VERSION ""

NS_ :

BS_:

BU_: MC_BRUSHED LISTENER COMMANDER REQUESTER

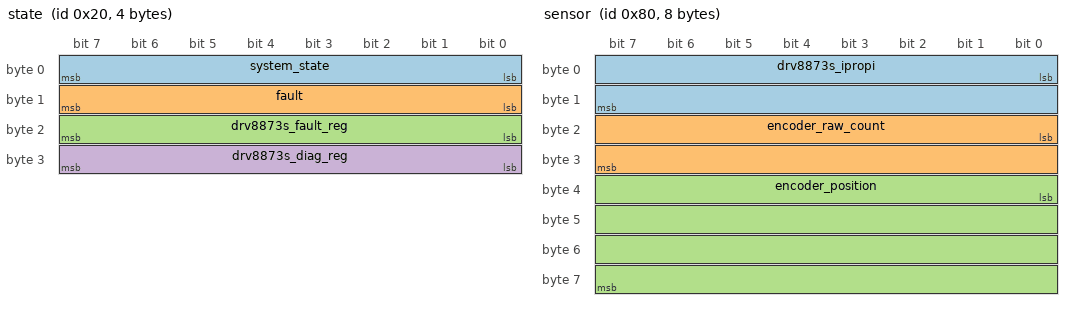
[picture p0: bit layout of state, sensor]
BO_ 32 state: 4 MC_BRUSHED
 SG_ system_state : 0|8@1+ (1,0) [0|255] ""  LISTENER
 SG_ fault : 8|8@1+ (1,0) [0|255] ""  LISTENER
 SG_ drv8873s_fault_reg : 16|8@1+ (1,0) [0|255] ""  LISTENER
 SG_ drv8873s_diag_reg : 24|8@1+ (1,0) [0|255] ""  LISTENER

BO_ 64 command_brushed: 6 COMMANDER
 SG_ node_id : 0|8@1+ (1,0) [0|255] ""  MC_BRUSHED
 SG_ control_mode M : 8|3@1+ (1,0) [0|7] ""  MC_BRUSHED
 SG_ enable : 11|1@1+ (1,0) [0|1] ""  MC_BRUSHED
 SG_ clear_faults : 12|1@1+ (1,0) [0|1] ""  MC_BRUSHED
 SG_ reserved0 : 13|3@1+ (1,0) [0|7] ""  MC_BRUSHED
 SG_ target_torque m1 : 16|32@1- (0.0001,0) [-214748.3648|214748.3647] "Nm"  MC_BRUSHED
 SG_ target_velocity m2 : 16|32@1- (0.001,0) [-2147483.648|2147483.647] "rad/s"  MC_BRUSHED
 SG_ target_position_rel m3 : 16|32@1- (0.001,0) [-2147483.648|2147483.647] "rad"  MC_BRUSHED
 SG_ target_hbridge_ol m4 : 16|32@1- (0.0001,0) [-1|1] ""  MC_BRUSHED

BO_ 96 command_brushed_zero: 1 COMMANDER
 SG_ node_id : 0|8@1+ (1,0) [0|255] ""  MC_BRUSHED

BO_ 128 sensor: 8 MC_BRUSHED
 SG_ drv8873s_ipropi : 0|16@1+ (1,0) [0|4095] "count"  LISTENER
 SG_ encoder_raw_count : 16|16@1- (1,0) [-32768|32767] "count"  LISTENER
 SG_ encoder_position : 32|32@1- (0.001,0) [-2147483.648|2147483.647] "rad"  LISTENER

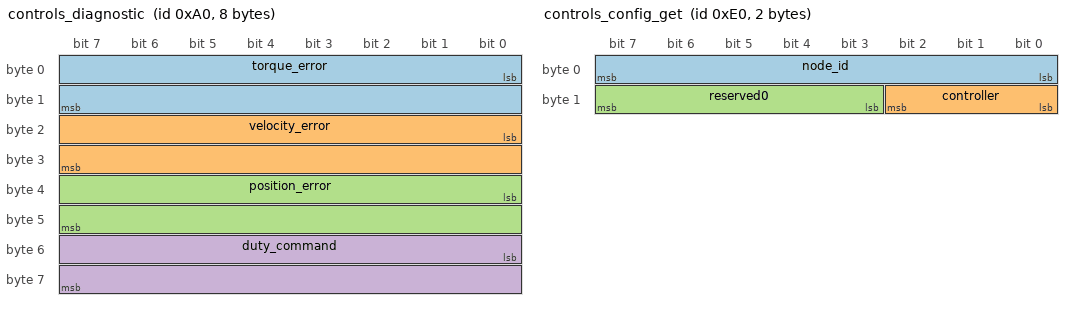
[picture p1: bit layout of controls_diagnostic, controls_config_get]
BO_ 160 controls_diagnostic: 8 MC_BRUSHED
 SG_ torque_error : 0|16@1- (0.001,0) [-32.768|32.767] "Nm"  LISTENER
 SG_ velocity_error : 16|16@1- (0.001,0) [-32.768|32.767] "rad/s"  LISTENER
 SG_ position_error : 32|16@1- (0.0001,0) [-3.2768|3.2767] "rad"  LISTENER
 SG_ duty_command : 48|16@1- (0.0001,0) [-1|1] ""  LISTENER

BO_ 192 controls_config_set: 8 COMMANDER
 SG_ node_id : 0|8@1+ (1,0) [0|255] ""  MC_BRUSHED
 SG_ controller M : 8|3@1+ (1,0) [0|7] ""  MC_BRUSHED
 SG_ reserved0 : 11|5@1+ (1,0) [0|31] ""  MC_BRUSHED
 SG_ torque_k_p m0 : 16|16@1+ (0.001,0) [0|65.535] ""  MC_BRUSHED
 SG_ velocity_k_p m1 : 16|16@1+ (0.001,0) [0|65.535] ""  MC_BRUSHED
 SG_ position_k_p m2 : 16|16@1+ (0.001,0) [0|65.535] ""  MC_BRUSHED
 SG_ torque_k_i m0 : 32|16@1+ (0.001,0) [0|65.535] ""  MC_BRUSHED
 SG_ velocity_k_i m1 : 32|16@1+ (0.001,0) [0|65.535] ""  MC_BRUSHED
 SG_ position_k_i m2 : 32|16@1+ (0.001,0) [0|65.535] ""  MC_BRUSHED
 SG_ torque_k_d m0 : 48|16@1+ (0.001,0) [0|65.535] ""  MC_BRUSHED
 SG_ velocity_k_d m1 : 48|16@1+ (0.001,0) [0|65.535] ""  MC_BRUSHED
 SG_ position_k_d m2 : 48|16@1+ (0.001,0) [0|65.535] ""  MC_BRUSHED

BO_ 224 controls_config_get: 2 REQUESTER
 SG_ node_id : 0|8@1+ (1,0) [0|255] ""  MC_BRUSHED
 SG_ controller M : 8|3@1+ (1,0) [0|7] ""  MC_BRUSHED
 SG_ reserved0 : 11|5@1+ (1,0) [0|31] ""  MC_BRUSHED

BO_ 256 controls_config_response: 8 MC_BRUSHED
 SG_ reserved0 : 0|8@1+ (1,0) [0|255] ""  REQUESTER
 SG_ controller M : 8|3@1+ (1,0) [0|7] ""  REQUESTER
 SG_ reserved1 : 11|5@1+ (1,0) [0|31] ""  REQUESTER
 SG_ torque_k_p m0 : 16|16@1+ (0.001,0) [0|65.535] ""  REQUESTER
 SG_ velocity_k_p m1 : 16|16@1+ (0.001,0) [0|65.535] ""  REQUESTER
 SG_ position_k_p m2 : 16|16@1+ (0.001,0) [0|65.535] ""  REQUESTER
 SG_ torque_k_i m0 : 32|16@1+ (0.001,0) [0|65.535] ""  REQUESTER
 SG_ velocity_k_i m1 : 32|16@1+ (0.001,0) [0|65.535] ""  REQUESTER
 SG_ position_k_i m2 : 32|16@1+ (0.001,0) [0|65.535] ""  REQUESTER
 SG_ torque_k_d m0 : 48|16@1+ (0.001,0) [0|65.535] ""  REQUESTER
 SG_ velocity_k_d m1 : 48|16@1+ (0.001,0) [0|65.535] ""  REQUESTER
 SG_ position_k_d m2 : 48|16@1+ (0.001,0) [0|65.535] ""  REQUESTER

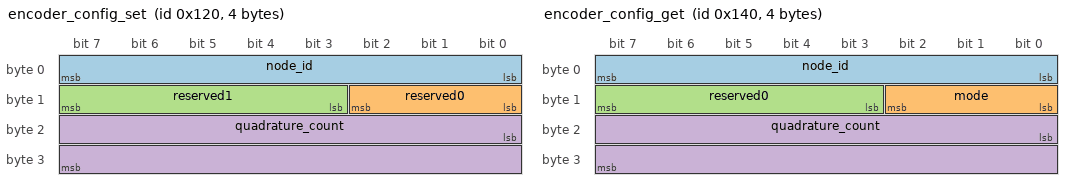
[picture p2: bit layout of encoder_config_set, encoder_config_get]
BO_ 288 encoder_config_set: 4 COMMANDER
 SG_ node_id : 0|8@1+ (1,0) [0|255] ""  MC_BRUSHED
 SG_ reserved0 : 8|3@1+ (1,0) [0|7] ""  MC_BRUSHED
 SG_ reserved1 : 11|5@1+ (1,0) [0|31] ""  MC_BRUSHED
 SG_ quadrature_count : 16|16@1+ (1,0) [0|65535] "count"  MC_BRUSHED

BO_ 320 encoder_config_get: 4 REQUESTER
 SG_ node_id : 0|8@1+ (1,0) [0|255] ""  MC_BRUSHED
 SG_ mode : 8|3@1+ (1,0) [0|7] ""  MC_BRUSHED
 SG_ reserved0 : 11|5@1+ (1,0) [0|31] ""  MC_BRUSHED
 SG_ quadrature_count : 16|16@1+ (1,0) [0|65535] "count"  MC_BRUSHED

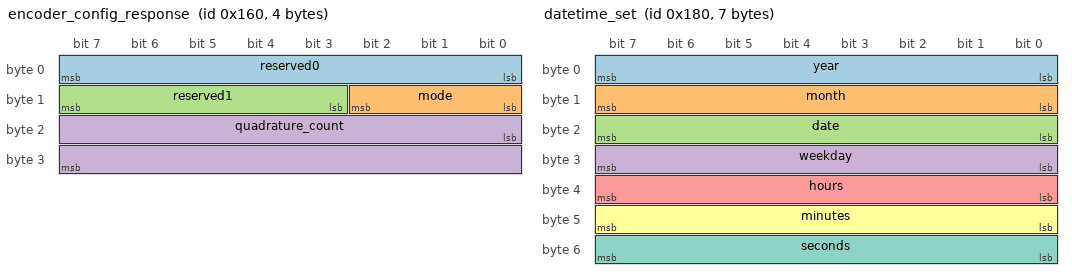
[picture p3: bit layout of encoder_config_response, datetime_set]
BO_ 352 encoder_config_response: 4 MC_BRUSHED
 SG_ reserved0 : 0|8@1+ (1,0) [0|255] ""  REQUESTER
 SG_ mode : 8|3@1+ (1,0) [0|7] ""  REQUESTER
 SG_ reserved1 : 11|5@1+ (1,0) [0|31] ""  REQUESTER
 SG_ quadrature_count : 16|16@1+ (1,0) [0|65535] "count"  REQUESTER

BO_ 384 datetime_set: 7 COMMANDER
 SG_ year : 0|8@1+ (1,0) [0|99] "year"  MC_BRUSHED
 SG_ month : 8|8@1+ (1,0) [1|12] "month"  MC_BRUSHED
 SG_ date : 16|8@1+ (1,0) [1|31] "day"  MC_BRUSHED
 SG_ weekday : 24|8@1+ (1,0) [1|7] "weekday"  MC_BRUSHED
 SG_ hours : 32|8@1+ (1,0) [0|23] "hour"  MC_BRUSHED
 SG_ minutes : 40|8@1+ (1,0) [0|59] "min"  MC_BRUSHED
 SG_ seconds : 48|8@1+ (1,0) [0|59] "sec"  MC_BRUSHED

BO_ 416 datetime_get: 0 REQUESTER

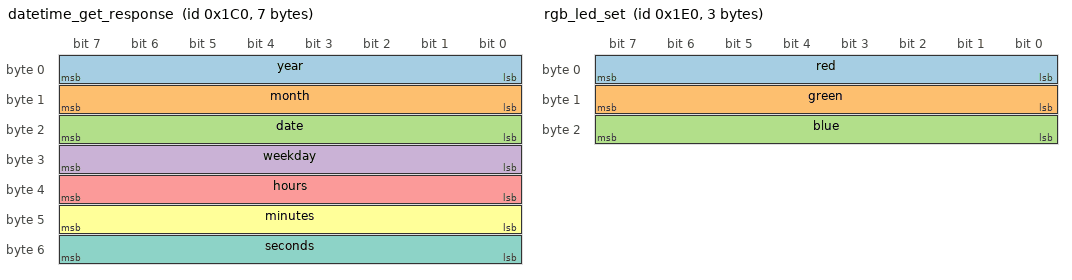
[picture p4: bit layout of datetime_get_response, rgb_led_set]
BO_ 448 datetime_get_response: 7 MC_BRUSHED
 SG_ year : 0|8@1+ (1,0) [0|99] "year"  REQUESTER
 SG_ month : 8|8@1+ (1,0) [1|12] "month"  REQUESTER
 SG_ date : 16|8@1+ (1,0) [1|31] "day"  REQUESTER
 SG_ weekday : 24|8@1+ (1,0) [1|7] "weekday"  REQUESTER
 SG_ hours : 32|8@1+ (1,0) [0|23] "hour"  REQUESTER
 SG_ minutes : 40|8@1+ (1,0) [0|59] "min"  REQUESTER
 SG_ seconds : 48|8@1+ (1,0) [0|59] "sec"  REQUESTER

BO_ 480 rgb_led_set: 3 REQUESTER
 SG_ red : 0|8@1+ (1,0) [0|255] ""  MC_BRUSHED
 SG_ green : 8|8@1+ (1,0) [0|255] ""  MC_BRUSHED
 SG_ blue : 16|8@1+ (1,0) [0|255] ""  MC_BRUSHED

BO_ 960 version_get: 0 REQUESTER

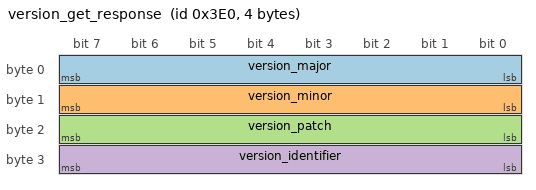
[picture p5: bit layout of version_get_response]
BO_ 992 version_get_response: 4 MC_BRUSHED
 SG_ version_major : 0|8@1+ (1,0) [0|255] "major"  REQUESTER
 SG_ version_minor : 8|8@1+ (1,0) [0|255] "minor"  REQUESTER
 SG_ version_patch : 16|8@1+ (1,0) [0|255] "patch"  REQUESTER
 SG_ version_identifier : 24|8@1+ (1,0) [0|255] "ascii"  REQUESTER

BA_DEF_  "BusType" STRING ;
BA_DEF_DEF_  "BusType" "CAN";
